# MCXN236 register map
Vendor: nxp.com; File version: 1.0
CPU: CM33 r2p0, little endian, MPU, FPU, VTOR, 3 interrupt priority bits
Registers are 32-bit, read-write, reset 0x0 unless marked. A register's access mark holds for its fields unless they carry their own. Offsets are from the block's base; [hi:lo] are bit positions; {n}, {i} and the like mark numbered series; 'fields as' and 'values as' point back to an identical list.

## EDMA_0_TCD — DMA TCD
Base 0x40081000
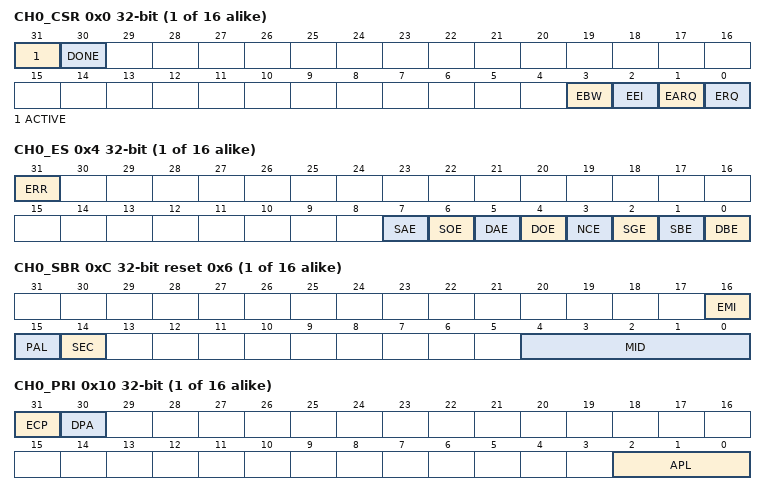
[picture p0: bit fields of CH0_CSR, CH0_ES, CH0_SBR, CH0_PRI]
{0x0+0x1000*i} CH{i}_CSR (i=0..15) — Channel Control and Status
  [31] ACTIVE ro — Channel Active
  [30] DONE write-1-clears — Channel Done
  [3] EBW — Enable Buffered Writes
    0=DISABLE (Buffered writes on system bus disabled); 1=ENABLE (Buffered writes on system bus enabled)
  [2] EEI — Enable Error Interrupt
    0=NO_ERROR (Error signal for corresponding channel does not generate error interrupt); 1=ERROR (Assertion of error signal for corresponding channel generates error interrupt request)
  [1] EARQ — Enable Asynchronous DMA Request
    0=DISABLE (Disable asynchronous DMA request for the channel); 1=ENABLE (Enable asynchronous DMA request for the channel)
  [0] ERQ — Enable DMA Request
    0=DISABLE (DMA hardware request signal for corresponding channel disabled); 1=ENABLE (DMA hardware request signal for corresponding channel enabled)
{0x4+0x1000*i} CH{i}_ES (i=0..15) — Channel Error Status
  [31] ERR write-1-clears — Error In Channel
    0=NO_ERROR (An error in this channel has not occurred); 1=ERROR (An error in this channel has occurred)
  [7] SAE ro — Source Address Error
    0=NO_ERROR (No source address configuration error); 1=ERROR (Last recorded error was a configuration error detected in the TCDn_SADDR field)
  [6] SOE ro — Source Offset Error
    0=NO_ERROR (No source offset configuration error); 1=ERROR (Last recorded error was a configuration error detected in the TCDn_SOFF field)
  [5] DAE ro — Destination Address Error
    0=NO_ERROR (No destination address configuration error); 1=ERROR (Last recorded error was a configuration error detected in the TCDn_DADDR field)
  [4] DOE ro — Destination Offset Error
    0=NO_ERROR (No destination offset configuration error); 1=ERROR (Last recorded error was a configuration error detected in the TCDn_DOFF field)
  [3] NCE ro — NBYTES/CITER Configuration Error
    0=NO_ERROR (No NBYTES/CITER configuration error); 1=ERROR (Last recorded error was a configuration error detected in the TCDn_NBYTES or TCDn_CITER fields)
  [2] SGE ro — Scatter/Gather Configuration Error
    0=NO_ERROR (No scatter/gather configuration error); 1=ERROR (Last recorded error was a configuration error detected in the TCDn_DLAST_SGA field)
  [1] SBE ro — Source Bus Error
    0=NO_ERROR (No source bus error); 1=ERROR (Last recorded error was bus error on source read)
  [0] DBE ro — Destination Bus Error
    0=NO_ERROR (No destination bus error); 1=ERROR (Last recorded error was bus error on destination write)
{0x8+0x1000*i} CH{i}_INT write-1-clears (i=0..15) — Channel Interrupt Status
  [0] INT write-1-clears — Interrupt Request
    0=INTERRUPT_CLEARED (Interrupt request for corresponding channel cleared); 1=INTERRUPT_ACTIVE (Interrupt request for corresponding channel active)
{0xC+0x1000*i} CH{i}_SBR reset 0x6 (i=0..15) — Channel System Bus
  [16] EMI — Enable Master ID Replication
    0=DISABLE (Master ID replication is disabled); 1=ENABLE (Master ID replication is enabled)
  [15] PAL — Privileged Access Level
    0=USER_PROTECTION (User protection level for DMA transfers); 1=PRIVILEGED_PROTECTION (Privileged protection level for DMA transfers)
  [14] SEC — Security Level
    0=NONSECURE_PROTECTION (Nonsecure protection level for DMA transfers); 1=SECURE_PROTECTION (Secure protection level for DMA transfers)
  [4:0] MID ro — Master ID
{0x10+0x1000*i} CH{i}_PRI (i=0..15) — Channel Priority
  [31] ECP — Enable Channel Preemption
    0=CANNOT_SUSPEND (Channel cannot be suspended by a higher-priority channel's service request); 1=SUSPEND (Channel can be temporarily suspended by a higher-priority channel's service request)
  [30] DPA — Disable Preempt Ability
    0=SUSPEND (Channel can suspend a lower-priority channel); 1=CANNOT_SUSPEND (Channel cannot suspend any other channel, regardless of channel priority)
  [2:0] APL — Arbitration Priority Level
{0x14+0x1000*i} CH{i}_MUX (i=0..15) — Channel Multiplexor Configuration
  [6:0] SRC — Service Request Source
{0x20+0x1000*i} TCD{i}_SADDR reset not defined (i=0..15) — TCD Source Address
  [31:0] SADDR — Source Address
{0x24+0x1000*i} TCD{i}_SOFF 16-bit reset not defined (i=0..15) — TCD Signed Source Address Offset
  [15:0] SOFF — Source Address Signed Offset
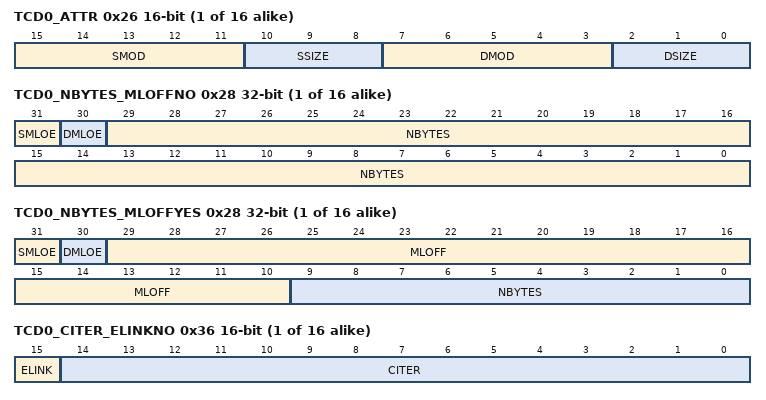
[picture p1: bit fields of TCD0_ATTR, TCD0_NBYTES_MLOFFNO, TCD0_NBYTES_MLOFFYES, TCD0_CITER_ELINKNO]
{0x26+0x1000*i} TCD{i}_ATTR 16-bit reset not defined (i=0..15) — TCD Transfer Attributes
  [15:11] SMOD — Source Address Modulo
    0=DISABLE (Source address modulo feature disabled); 1=ENABLE (Source address modulo feature enabled for any non-zero value [1-31])
  [10:8] SSIZE — Source Data Transfer Size
    0=EIGHT_BIT (8-bit); 1=SIXTEEN_BIT (16-bit); 2=THIRTYTWO_BIT (32-bit); 3=SIXTYFOUR_BIT (64-bit); 4=SIXTEEN_BYTE (16-byte); 5=THIRTYTWO_BYTE (32-byte)
  [7:3] DMOD — Destination Address Modulo
  [2:0] DSIZE — Destination Data Transfer Size
{0x28+0x1000*i} TCD{i}_NBYTES_MLOFFNO reset not defined (NBYTES view) (i=0..15) — TCD Transfer Size Without Minor Loop Offsets
  [31] SMLOE — Source Minor Loop Offset Enable
    0=OFFSET_NOT_APPLIED (Minor loop offset not applied to SADDR); 1=OFFSET_APPLIED (Minor loop offset applied to SADDR)
  [30] DMLOE — Destination Minor Loop Offset Enable
    0=OFFSET_NOT_APPLIED (Minor loop offset not applied to DADDR); 1=OFFSET_APPLIED (Minor loop offset applied to DADDR)
  [29:0] NBYTES — Number of Bytes To Transfer Per Service Request
{0x28+0x1000*i} TCD{i}_NBYTES_MLOFFYES reset not defined (NBYTES view) (i=0..15) — TCD Transfer Size with Minor Loop Offsets
  [31] SMLOE — Source Minor Loop Offset Enable
    values as TCD0_NBYTES_MLOFFNO.SMLOE
  [30] DMLOE — Destination Minor Loop Offset Enable
    values as TCD0_NBYTES_MLOFFNO.DMLOE
  [29:10] MLOFF — Minor Loop Offset
  [9:0] NBYTES — Number of Bytes To Transfer Per Service Request
{0x2C+0x1000*i} TCD{i}_SLAST_SDA reset not defined (i=0..15) — TCD Last Source Address Adjustment / Store DADDR Address
  [31:0] SLAST_SDA — Last Source Address Adjustment / Store DADDR Address
{0x30+0x1000*i} TCD{i}_DADDR reset not defined (i=0..15) — TCD Destination Address
  [31:0] DADDR — Destination Address
{0x34+0x1000*i} TCD{i}_DOFF 16-bit reset not defined (i=0..15) — TCD Signed Destination Address Offset
  [15:0] DOFF — Destination Address Signed Offset
{0x36+0x1000*i} TCD{i}_CITER_ELINKNO 16-bit reset not defined (CITER view) (i=0..15) — TCD Current Major Loop Count (Minor Loop Channel Linking Disabled)
  [15] ELINK — Enable Link
    0=DISABLE (Channel-to-channel linking disabled); 1=ENABLE (Channel-to-channel linking enabled)
  [14:0] CITER — Current Major Iteration Count
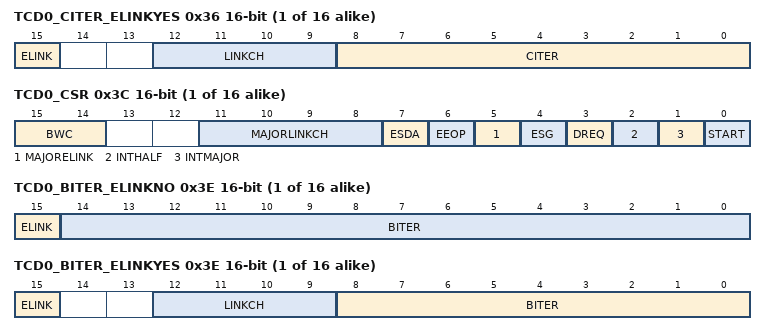
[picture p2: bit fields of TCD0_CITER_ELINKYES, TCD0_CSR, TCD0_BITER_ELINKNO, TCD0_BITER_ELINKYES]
{0x36+0x1000*i} TCD{i}_CITER_ELINKYES 16-bit reset not defined (CITER view) (i=0..15) — TCD Current Major Loop Count (Minor Loop Channel Linking Enabled)
  [15] ELINK — Enable Link
    values as TCD0_CITER_ELINKNO.ELINK
  [12:9] LINKCH — Minor Loop Link Channel Number
  [8:0] CITER — Current Major Iteration Count
{0x38+0x1000*i} TCD{i}_DLAST_SGA reset not defined (i=0..15) — TCD Last Destination Address Adjustment / Scatter Gather Address
  [31:0] DLAST_SGA — Last Destination Address Adjustment / Scatter Gather Address
{0x3C+0x1000*i} TCD{i}_CSR 16-bit (reset mask 0x1) (i=0..15) — TCD Control and Status
  [15:14] BWC — Bandwidth Control
    0=NO_STALL (No eDMA engine stalls); 2=ENGINE_STALLS_FOUR (eDMA engine stalls for 4 cycles after each R/W); 3=ENGINE_STALLS_EIGHT (eDMA engine stalls for 8 cycles after each R/W)
  [11:8] MAJORLINKCH — Major Loop Link Channel Number
  [7] ESDA — Enable Store Destination Address
    0=DISABLE (Ability to store destination address to system memory disabled); 1=ENABLE (Ability to store destination address to system memory enabled)
  [6] EEOP — Enable End-Of-Packet Processing
    0=DISABLE (End-of-packet operation disabled); 1=ENABLE (End-of-packet hardware input signal enabled)
  [5] MAJORELINK — Enable Link When Major Loop Complete
    values as TCD0_CITER_ELINKNO.ELINK
  [4] ESG — Enable Scatter/Gather Processing
    0=NORMAL_FORMAT (Current channel's TCD is normal format); 1=SCATTER_GATHER_FORMAT (Current channel's TCD specifies scatter/gather format.)
  [3] DREQ — Disable Request
    0=CHANNEL_NOT_AFFECTED (No operation); 1=ERQ_FIELD_CLEAR (Clear the ERQ field to 0 upon major loop completion, thus disabling hardware service requests)
  [2] INTHALF — Enable Interrupt If Major Counter Half-complete
    0=DISABLE (Halfway point interrupt disabled); 1=ENABLE (Halfway point interrupt enabled)
  [1] INTMAJOR — Enable Interrupt If Major count complete
    0=DISABLE (End-of-major loop interrupt disabled); 1=ENABLE (End-of-major loop interrupt enabled)
  [0] START — Channel Start
    0=CHANNEL_NOT_STARTED (Channel not explicitly started); 1=CHANNEL_STARTED (Channel explicitly started via a software-initiated service request)
{0x3E+0x1000*i} TCD{i}_BITER_ELINKNO 16-bit reset not defined (BITER view) (i=0..15) — TCD Beginning Major Loop Count (Minor Loop Channel Linking Disabled)
  [15] ELINK — Enables Link
    values as TCD0_CITER_ELINKNO.ELINK
  [14:0] BITER — Starting Major Iteration Count
{0x3E+0x1000*i} TCD{i}_BITER_ELINKYES 16-bit reset not defined (BITER view) (i=0..15) — TCD Beginning Major Loop Count (Minor Loop Channel Linking Enabled)
  [15] ELINK — Enable Link
    values as TCD0_CITER_ELINKNO.ELINK
  [12:9] LINKCH — Link Channel Number
  [8:0] BITER — Starting Major Iteration Count

## EDMA_1_TCD — DMA TCD
Base 0x400A1000
Registers as EDMA_0_TCD, without CH{n}_CSR (n=8..15), CH{n}_ES (n=8..15), CH{n}_INT (n=8..15), CH{n}_SBR (n=8..15), CH{n}_PRI (n=8..15), CH{n}_MUX (n=8..15), TCD{n}_SADDR (n=8..15), TCD{n}_SOFF (n=8..15), TCD{n}_ATTR (n=8..15), TCD{n}_NBYTES_MLOFFNO (n=8..15), TCD{n}_NBYTES_MLOFFYES (n=8..15), TCD{n}_SLAST_SDA (n=8..15), TCD{n}_DADDR (n=8..15), TCD{n}_DOFF (n=8..15), TCD{n}_CITER_ELINKNO (n=8..15), TCD{n}_CITER_ELINKYES (n=8..15), TCD{n}_DLAST_SGA (n=8..15), TCD{n}_CSR (n=8..15), TCD{n}_BITER_ELINKNO (n=8..15), TCD{n}_BITER_ELINKYES (n=8..15); these are added or differ:
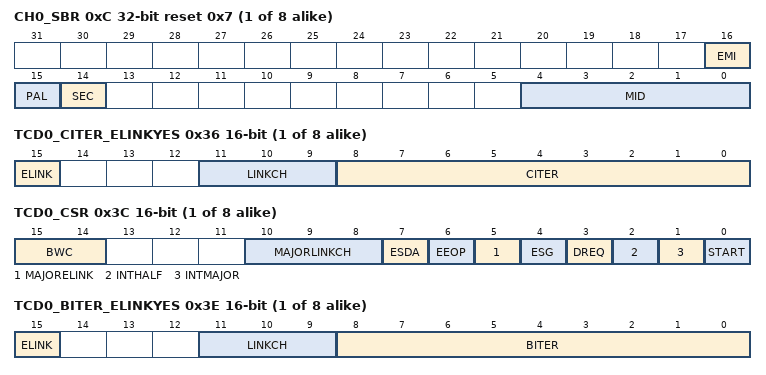
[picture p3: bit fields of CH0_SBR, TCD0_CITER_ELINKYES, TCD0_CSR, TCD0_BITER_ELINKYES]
{0xC+0x1000*i} CH{i}_SBR reset 0x7 (i=0..7) — Channel System Bus
  fields as EDMA_0_TCD.CH0_SBR
{0x36+0x1000*i} TCD{i}_CITER_ELINKYES 16-bit reset not defined (CITER view) (i=0..7) — TCD Current Major Loop Count (Minor Loop Channel Linking Enabled)
  [15] ELINK — Enable Link
    0=DISABLE (Channel-to-channel linking disabled); 1=ENABLE (Channel-to-channel linking enabled)
  [11:9] LINKCH — Minor Loop Link Channel Number
  [8:0] CITER — Current Major Iteration Count
{0x3C+0x1000*i} TCD{i}_CSR 16-bit (reset mask 0x1) (i=0..7) — TCD Control and Status
  [15:14] BWC — Bandwidth Control
    0=NO_STALL (No eDMA engine stalls); 2=ENGINE_STALLS_FOUR (eDMA engine stalls for 4 cycles after each R/W); 3=ENGINE_STALLS_EIGHT (eDMA engine stalls for 8 cycles after each R/W)
  [10:8] MAJORLINKCH — Major Loop Link Channel Number
  [7] ESDA — Enable Store Destination Address
    0=DISABLE (Ability to store destination address to system memory disabled); 1=ENABLE (Ability to store destination address to system memory enabled)
  [6] EEOP — Enable End-Of-Packet Processing
    0=DISABLE (End-of-packet operation disabled); 1=ENABLE (End-of-packet hardware input signal enabled)
  [5] MAJORELINK — Enable Link When Major Loop Complete
    values as TCD0_CITER_ELINKYES.ELINK
  [4] ESG — Enable Scatter/Gather Processing
    0=NORMAL_FORMAT (Current channel's TCD is normal format); 1=SCATTER_GATHER_FORMAT (Current channel's TCD specifies scatter/gather format.)
  [3] DREQ — Disable Request
    0=CHANNEL_NOT_AFFECTED (No operation); 1=ERQ_FIELD_CLEAR (Clear the ERQ field to 0 upon major loop completion, thus disabling hardware service requests)
  [2] INTHALF — Enable Interrupt If Major Counter Half-complete
    0=DISABLE (Halfway point interrupt disabled); 1=ENABLE (Halfway point interrupt enabled)
  [1] INTMAJOR — Enable Interrupt If Major count complete
    0=DISABLE (End-of-major loop interrupt disabled); 1=ENABLE (End-of-major loop interrupt enabled)
  [0] START — Channel Start
    0=CHANNEL_NOT_STARTED (Channel not explicitly started); 1=CHANNEL_STARTED (Channel explicitly started via a software-initiated service request)
{0x3E+0x1000*i} TCD{i}_BITER_ELINKYES 16-bit reset not defined (BITER view) (i=0..7) — TCD Beginning Major Loop Count (Minor Loop Channel Linking Enabled)
  [15] ELINK — Enable Link
    values as TCD0_CITER_ELINKYES.ELINK
  [11:9] LINKCH — Link Channel Number
  [8:0] BITER — Starting Major Iteration Count
